# CY8C5888LTI_LP097 register map
File version: 0.1
CY8C58LP
Registers are 8-bit, read-write, no defined reset value unless marked. A register's access mark holds for its fields unless they carry their own. Offsets are from the block's base; lines under a group give offsets from that group; [hi:lo] are bit positions; {n}, {i} and the like mark numbered series; 'fields as' and 'values as' point back to an identical list; <NAME> marks a mode.

## Memory map
0x00000000 MultiJog_Status
0x00000000 MultiJog_Reset — Count7 debug registers
0x00000000 LCD_DB_OutEnable
0x00000000 PWM_VoltageA
0x00000000 VDAC8_OverVoltageA
0x00000000 ADC_VoltageA — SAR ADC
0x00000000 Comp_OverVoltageA
0x00000000 RegulatorControl
0x00000000 MultiJog_FreqMeter — Count7 debug registers
0x00000000 FanCtrl
0x00000000 Count7_OverAmperageA — Count7 debug registers
0x00000000 Count7_OverVoltageA — Count7 debug registers
0x00000000 Count7_VoltageA_Ex — Count7 debug registers
0x00000000 Count7_OverVoltageB — Count7 debug registers
0x00000000 Comp_OverAmperageB
0x00000000 Count7_OverAmperageB — Count7 debug registers
0x00000000 StatusAdcVoltageA
0x00000000 PGA_AmperageB
0x00000000 VDAC8_OverAmperageB
0x00000000 StatusAdcVoltageB
0x00000000 Comp_OverAmperageA
0x00000000 VDAC8_OverAmperageA
0x00000000 PGA_AmperageA
0x00000000 PWM_LcdBackLight
0x00000000 RegulatorStatus
0x00000000 ADC_VoltageB — SAR ADC
0x00000000 PGA_OverVoltageB
0x00000000 PWM_VoltageA_Ex
0x00000000 PWM_VoltageB_Ex
0x00000000 Count7_VoltageB_Ex — Count7 debug registers
0x00000000 PGA_OverVoltageA
0x00000000 Comp_OverVoltageB
0x00000000 VDAC8_OverVoltageB
0x00000000 MultiJog
0x00000000 MultiJog_Cnt8
0x00000000 BtnOk_Reset — Count7 debug registers
0x00000000 Buttons
0x00000000 PWM_VoltageB
0x00000000 ADC_Amperage

## MultiJog_Status
Base 0x00000000
0x40006469 MultiJog_Status_STATUS_REG
0x40006489 MultiJog_Status_MASK_REG
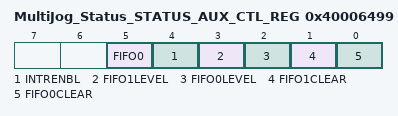
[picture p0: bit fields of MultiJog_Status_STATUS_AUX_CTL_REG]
0x40006499 MultiJog_Status_STATUS_AUX_CTL_REG
  [5] FIFO0 — FIFO0 clear
    1=ENABLED (Enable counter); 0=DISABLED (Disable counter)
  [4] INTRENBL — Enables or disables the Interrupt
    1=ENABLED (Interrupt enabled); 0=DISABLED (Interrupt disabled)
  [3] FIFO1LEVEL — FIFO level
    1=ENABLED (FIFO LVL: input mode: FIFO at least 1/2 empty; output mode: FIFO at least 1/2 full); 0=DISABLED (FIFO LVL: input mode: FIFO not full; output mode: FIFO not empty)
  [2] FIFO0LEVEL — FIFO level
    values as FIFO1LEVEL
  [1] FIFO1CLEAR — FIFO clear
    1=ENABLED (Clear FIFO state); 0=DISABLED (Normal FIFO operation)
  [0] FIFO0CLEAR — FIFO clear
    values as FIFO1CLEAR

## MultiJog_Reset — Count7 debug registers
Base 0x00000000
0x4000647E COUNT 7-bit — Count value register
0x4000648E PERIOD 7-bit — Count7 period register

## LCD_DB_OutEnable
Base 0x00000000
0x4000647B LCD_DB_OutEnable_CONTROL_REG

## PWM_VoltageA
Base 0x00000000
0x40006420 PWM_VoltageA_COMPARE_1 16-bit — UDB.D0 - Assigned Compare1 Value
0x40006430 PWM_VoltageA_COMPARE_2 16-bit — UDB.D1 - Assigned Compare2 Value
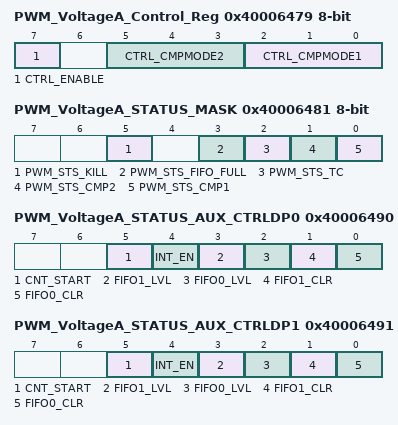
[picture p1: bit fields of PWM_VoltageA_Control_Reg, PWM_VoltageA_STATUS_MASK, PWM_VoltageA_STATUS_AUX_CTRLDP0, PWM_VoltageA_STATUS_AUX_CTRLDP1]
0x40006479 PWM_VoltageA_Control_Reg — UDB Control Register - Assigned Control Register Value
  [7] CTRL_ENABLE — Enable the PWM
  [5:3] CTRL_CMPMODE2 — Compare mode 2
  [2:0] CTRL_CMPMODE1 — Compare mode 1
0x40006481 PWM_VoltageA_STATUS_MASK — UDB Status bits Interrupt Mask Enable Register
  [5] PWM_STS_KILL ro — Enables the Interrupt on Kill
  [3] PWM_STS_FIFO_FULL ro — FIFO Full Status Mask
  [2] PWM_STS_TC ro — Enables the Interrupt on Terminal Count
  [1] PWM_STS_CMP2 ro — Enables the Interrupt on Compare 2
  [0] PWM_STS_CMP1 ro — Enables the Interrupt on Compare 1
0x40006490 PWM_VoltageA_STATUS_AUX_CTRLDP0 — UDB Auxilliary Control Register
  [5] CNT_START — FIFO0 clear
    0=E_CNT_START0 (Disable counter); 1=E_CNT_START1 (Enable counter)
  [4] INT_EN
    0=E_INT_EN0 (Interrupt disabled); 1=E_INT_EN1 (Interrupt enabled)
  [3] FIFO1_LVL — FIFO level
    0=E_FIFO_LVL_0 (FIFO LVL: input mode: FIFO not full; output mode: FIFO not empty); 1=E_FIFO_LVL_1 (FIFO LVL: input mode: FIFO at least 1/2 empty; output mode: FIFO at least 1/2 full)
  [2] FIFO0_LVL — FIFO level
    values as FIFO1_LVL
  [1] FIFO1_CLR — FIFO1 clear
    0=E_FIFO_CLR_0 (Normal FIFO operation); 1=E_FIFO_CLR_1 (Clear FIFO state)
  [0] FIFO0_CLR — FIFO0 clear
    values as FIFO1_CLR
0x40006491 PWM_VoltageA_STATUS_AUX_CTRLDP1 — UDB Auxilliary Control Register
  fields as PWM_VoltageA_STATUS_AUX_CTRLDP0
